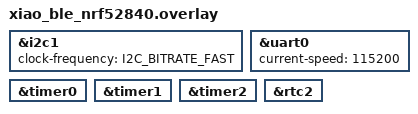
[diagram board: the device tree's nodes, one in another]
&i2c1 {
	status = "okay";
	clock-frequency = <I2C_BITRATE_FAST>; /* 400 kHz */
};
&uart0 {current-speed = <115200>;};
&timer0 {status = "okay";};
&timer1 {status = "okay";};
&timer2 {status = "okay";};
&rtc2 {status = "okay";};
